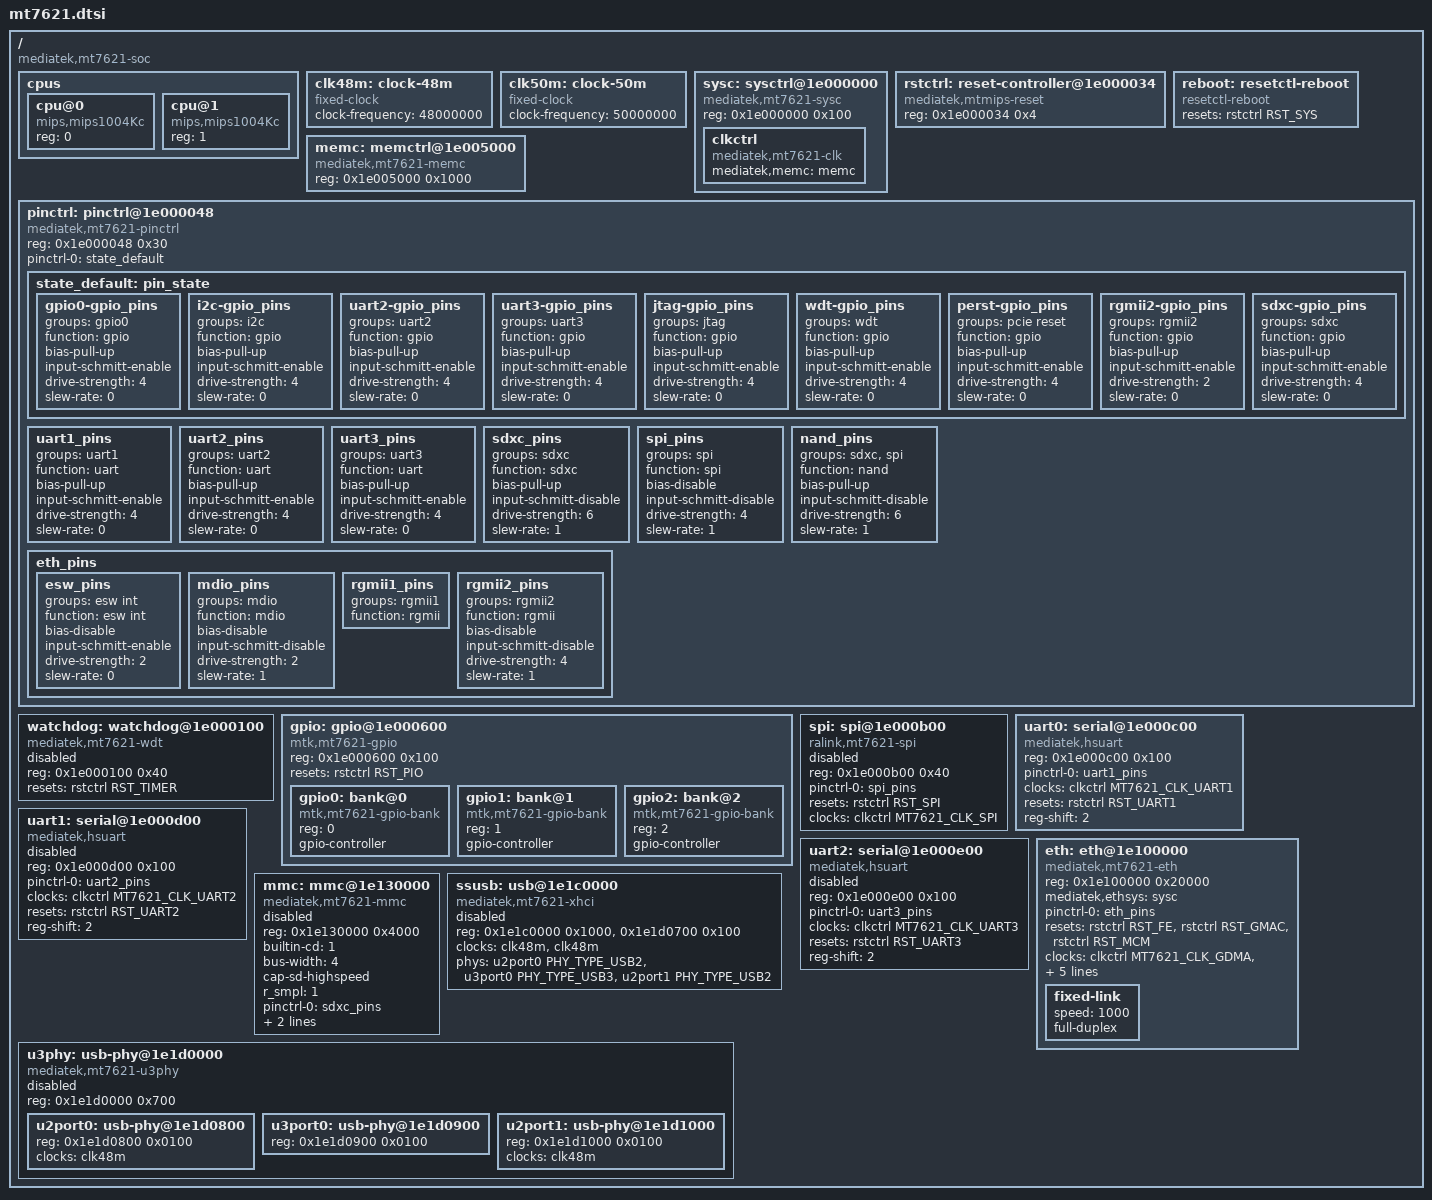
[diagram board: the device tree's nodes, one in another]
// SPDX-License-Identifier: GPL-2.0
/*
 * Copyright (C) 2022 MediaTek Inc. All rights reserved.
 *
 * Author: Weijie Gao <weijie.gao@mediatek.com>
 */

#include <dt-bindings/clock/mt7621-clk.h>
#include <dt-bindings/reset/mt7621-reset.h>
#include <dt-bindings/phy/phy.h>

/ {
	#address-cells = <1>;
	#size-cells = <1>;
	compatible = "mediatek,mt7621-soc";

	cpus {
		#address-cells = <1>;
		#size-cells = <0>;

		cpu@0 {
			compatible = "mips,mips1004Kc";
			reg = <0>;
			device_type = "cpu";
		};

		cpu@1 {
			compatible = "mips,mips1004Kc";
			reg = <1>;
			device_type = "cpu";
		};
	};

	clk48m: clock-48m {
		compatible = "fixed-clock";

		clock-frequency = <48000000>;

		#clock-cells = <0>;
	};

	clk50m: clock-50m {
		compatible = "fixed-clock";

		clock-frequency = <50000000>;

		#clock-cells = <0>;
	};

	sysc: sysctrl@1e000000 {
		compatible = "mediatek,mt7621-sysc", "syscon";
		reg = <0x1e000000 0x100>;

		clkctrl: clkctrl {
			compatible = "mediatek,mt7621-clk";
			mediatek,memc = <&memc>;

			#clock-cells = <1>;
		};
	};

	rstctrl: reset-controller@1e000034 {
		compatible = "mediatek,mtmips-reset";
		reg = <0x1e000034 0x4>;
		#reset-cells = <1>;
	};

	reboot: resetctl-reboot {
		compatible = "resetctl-reboot";

		resets = <&rstctrl RST_SYS>;
		reset-names = "sysreset";
	};

	memc: memctrl@1e005000 {
		compatible = "mediatek,mt7621-memc", "syscon";
		reg = <0x1e005000 0x1000>;
	};

	pinctrl: pinctrl@1e000048 {
		compatible = "mediatek,mt7621-pinctrl";
		reg = <0x1e000048 0x30>;

		pinctrl-names = "default";
		pinctrl-0 = <&state_default>;

		state_default: pin_state {
			gpio0-gpio_pins {
				groups = "gpio0";
				function = "gpio";
				bias-pull-up;
				input-schmitt-enable;
				drive-strength = <4>;
				slew-rate = <0>;
			};

			i2c-gpio_pins {
				groups = "i2c";
				function = "gpio";
				bias-pull-up;
				input-schmitt-enable;
				drive-strength = <4>;
				slew-rate = <0>;
			};

			uart2-gpio_pins {
				groups = "uart2";
				function = "gpio";
				bias-pull-up;
				input-schmitt-enable;
				drive-strength = <4>;
				slew-rate = <0>;
			};

			uart3-gpio_pins {
				groups = "uart3";
				function = "gpio";
				bias-pull-up;
				input-schmitt-enable;
				drive-strength = <4>;
				slew-rate = <0>;
			};

			jtag-gpio_pins {
				groups = "jtag";
				function = "gpio";
				bias-pull-up;
				input-schmitt-enable;
				drive-strength = <4>;
				slew-rate = <0>;
			};

			wdt-gpio_pins {
				groups = "wdt";
				function = "gpio";
				bias-pull-up;
				input-schmitt-enable;
				drive-strength = <4>;
				slew-rate = <0>;
			};

			perst-gpio_pins {
				groups = "pcie reset";
				function = "gpio";
				bias-pull-up;
				input-schmitt-enable;
				drive-strength = <4>;
				slew-rate = <0>;
			};

			rgmii2-gpio_pins {
				groups = "rgmii2";
				function = "gpio";
				bias-pull-up;
				input-schmitt-enable;
				drive-strength = <2>;
				slew-rate = <0>;
			};

			sdxc-gpio_pins {
				groups = "sdxc";
				function = "gpio";
				bias-pull-up;
				input-schmitt-enable;
				drive-strength = <4>;
				slew-rate = <0>;
			};
		};

		uart1_pins: uart1_pins {
			groups = "uart1";
			function = "uart";
			bias-pull-up;
			input-schmitt-enable;
			drive-strength = <4>;
			slew-rate = <0>;
		};

		uart2_pins: uart2_pins {
			groups = "uart2";
			function = "uart";
			bias-pull-up;
			input-schmitt-enable;
			drive-strength = <4>;
			slew-rate = <0>;
		};

		uart3_pins: uart3_pins {
			groups = "uart3";
			function = "uart";
			bias-pull-up;
			input-schmitt-enable;
			drive-strength = <4>;
			slew-rate = <0>;
		};

		sdxc_pins: sdxc_pins {
			groups = "sdxc";
			function = "sdxc";
			bias-pull-up;
			input-schmitt-disable;
			drive-strength = <6>;
			slew-rate = <1>;
		};

		spi_pins: spi_pins {
			groups = "spi";
			function = "spi";
			bias-disable;
			input-schmitt-disable;
			drive-strength = <4>;
			slew-rate = <1>;
		};

		nand_pins: nand_pins {
			groups = "sdxc", "spi";
			function = "nand";
			bias-pull-up;
			input-schmitt-disable;
			drive-strength = <6>;
			slew-rate = <1>;
		};

		eth_pins: eth_pins {
			esw_pins {
				groups = "esw int";
				function = "esw int";
				bias-disable;
				input-schmitt-enable;
				drive-strength = <2>;
				slew-rate = <0>;
			};

			mdio_pins {
				groups = "mdio";
				function = "mdio";
				bias-disable;
				input-schmitt-disable;
				drive-strength = <2>;
				slew-rate = <1>;
			};

			rgmii1_pins {
				groups = "rgmii1";
				function = "rgmii";
			};

			rgmii2_pins {
				groups = "rgmii2";
				function = "rgmii";
				bias-disable;
				input-schmitt-disable;
				drive-strength = <4>;
				slew-rate = <1>;
			};
		};
	};

	watchdog: watchdog@1e000100 {
		compatible = "mediatek,mt7621-wdt";
		reg = <0x1e000100 0x40>;

		resets = <&rstctrl RST_TIMER>;
		reset-names = "wdt";

		status = "disabled";
	};

	gpio: gpio@1e000600 {
		compatible = "mtk,mt7621-gpio";
		reg = <0x1e000600 0x100>;
		#address-cells = <1>;
		#size-cells = <0>;
		resets = <&rstctrl RST_PIO>;
		reset-names = "pio";

		gpio0: bank@0 {
			compatible = "mtk,mt7621-gpio-bank";
			reg = <0>;
			gpio-controller;
			#gpio-cells = <2>;
		};

		gpio1: bank@1 {
			compatible = "mtk,mt7621-gpio-bank";
			reg = <1>;
			gpio-controller;
			#gpio-cells = <2>;
		};

		gpio2: bank@2 {
			compatible = "mtk,mt7621-gpio-bank";
			reg = <2>;
			gpio-controller;
			#gpio-cells = <2>;
		};
	};

	spi: spi@1e000b00 {
		compatible = "ralink,mt7621-spi";
		reg = <0x1e000b00 0x40>;

		status = "disabled";

		pinctrl-names = "default";
		pinctrl-0 = <&spi_pins>;

		resets = <&rstctrl RST_SPI>;
		reset-names = "spi";

		clocks = <&clkctrl MT7621_CLK_SPI>;

		#address-cells = <1>;
		#size-cells = <0>;
	};

	uart0: serial@1e000c00 {
		compatible = "mediatek,hsuart", "ns16550a";
		reg = <0x1e000c00 0x100>;

		pinctrl-names = "default";
		pinctrl-0 = <&uart1_pins>;

		clocks = <&clkctrl MT7621_CLK_UART1>;

		resets = <&rstctrl RST_UART1>;

		reg-shift = <2>;
	};

	uart1: serial@1e000d00 {
		compatible = "mediatek,hsuart", "ns16550a";
		reg = <0x1e000d00 0x100>;

		pinctrl-names = "default";
		pinctrl-0 = <&uart2_pins>;

		clocks = <&clkctrl MT7621_CLK_UART2>;

		resets = <&rstctrl RST_UART2>;

		reg-shift = <2>;

		status = "disabled";
	};

	uart2: serial@1e000e00 {
		compatible = "mediatek,hsuart", "ns16550a";
		reg = <0x1e000e00 0x100>;

		pinctrl-names = "default";
		pinctrl-0 = <&uart3_pins>;

		clocks = <&clkctrl MT7621_CLK_UART3>;

		resets = <&rstctrl RST_UART3>;

		reg-shift = <2>;

		status = "disabled";
	};

	eth: eth@1e100000 {
		compatible = "mediatek,mt7621-eth";
		reg = <0x1e100000 0x20000>;
		mediatek,ethsys = <&sysc>;

		pinctrl-names = "default";
		pinctrl-0 = <&eth_pins>;

		resets = <&rstctrl RST_FE>, <&rstctrl RST_GMAC>, <&rstctrl RST_MCM>;
		reset-names = "fe", "gmac", "mcm";

		clocks = <&clkctrl MT7621_CLK_GDMA>,
			 <&clkctrl MT7621_CLK_ETH>;
		clock-names = "gmac", "fe";

		mediatek,gmac-id = <0>;
		phy-mode = "rgmii";
		mediatek,switch = "mt7530";
		mediatek,mcm;

		fixed-link {
			speed = <1000>;
			full-duplex;
		};
	};

	mmc: mmc@1e130000 {
		compatible = "mediatek,mt7621-mmc";
		reg = <0x1e130000 0x4000>;

		builtin-cd = <1>;
		bus-width = <4>;
		cap-sd-highspeed;
		r_smpl = <1>;

		pinctrl-names = "default";
		pinctrl-0 = <&sdxc_pins>;

		clocks = <&clk50m>, <&clkctrl MT7621_CLK_SHXC>;
		clock-names = "source", "hclk";

		resets = <&rstctrl RST_SDXC>;

		status = "disabled";
	};

	ssusb: usb@1e1c0000 {
		compatible = "mediatek,mt7621-xhci", "mediatek,mtk-xhci";
		reg = <0x1e1c0000 0x1000>, <0x1e1d0700 0x100>;
		reg-names = "mac", "ippc";

		clocks = <&clk48m>, <&clk48m>;
		clock-names = "sys_ck", "ref_ck";

		phys = <&u2port0 PHY_TYPE_USB2>,
		       <&u3port0 PHY_TYPE_USB3>,
		       <&u2port1 PHY_TYPE_USB2>;

		status = "disabled";
	};

	u3phy: usb-phy@1e1d0000 {
		compatible = "mediatek,mt7621-u3phy",
			     "mediatek,generic-tphy-v1";
		reg = <0x1e1d0000 0x700>;
		#address-cells = <1>;
		#size-cells = <1>;
		ranges;
		status = "disabled";

		u2port0: usb-phy@1e1d0800 {
			reg = <0x1e1d0800 0x0100>;
			#phy-cells = <1>;
			clocks = <&clk48m>;
			clock-names = "ref";
		};

		u3port0: usb-phy@1e1d0900 {
			reg = <0x1e1d0900 0x0100>;
			#phy-cells = <1>;
		};

		u2port1: usb-phy@1e1d1000 {
			reg = <0x1e1d1000 0x0100>;
			#phy-cells = <1>;
			clocks = <&clk48m>;
			clock-names = "ref";
		};
	};
};
